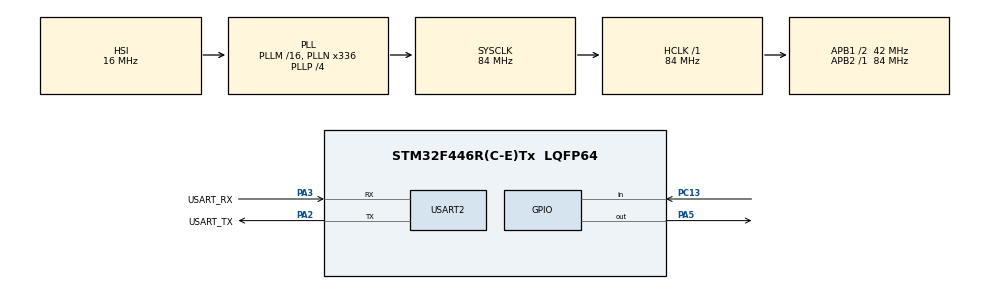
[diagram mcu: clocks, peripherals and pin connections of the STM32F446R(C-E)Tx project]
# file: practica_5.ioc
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Mcu.Family=STM32F4
Mcu.Name=STM32F446R(C-E)Tx
Mcu.Package=LQFP64
NVIC.PriorityGroup=NVIC_PRIORITYGROUP_0
PA13.GPIO_Label=TMS
PA13.Signal=SYS_JTMS-SWDIO
PA14.GPIO_Label=TCK
PA14.Signal=SYS_JTCK-SWCLK
PA2.GPIO_Label=USART_TX
PA2.Mode=Asynchronous
PA2.Signal=USART2_TX
PA3.GPIO_Label=USART_RX
PA3.Mode=Asynchronous
PA3.Signal=USART2_RX
PA5.Signal=GPIO_Output
PB3.GPIO_Label=SWO
PB3.Signal=SYS_JTDO-SWO
PC13.Signal=GPIO_Input
PC14-OSC32_IN.Signal=RCC_OSC32_IN
PC15-OSC32_OUT.Signal=RCC_OSC32_OUT
PH0-OSC_IN.Signal=RCC_OSC_IN
PH1-OSC_OUT.Signal=RCC_OSC_OUT
ProjectManager.HeapSize=0x200
ProjectManager.StackSize=0x400
ProjectManager.TargetToolchain=STM32CubeIDE
RCC.AHBFreq_Value=84000000
RCC.APB1CLKDivider=RCC_HCLK_DIV2
RCC.APB1Freq_Value=42000000
RCC.APB1TimFreq_Value=84000000
RCC.APB2Freq_Value=84000000
RCC.APB2TimFreq_Value=84000000
RCC.CortexFreq_Value=84000000
RCC.FLatency-AdvancedSettings=FLASH_LATENCY_2
RCC.HCLKFreq_Value=84000000
RCC.HSE_VALUE=8000000
RCC.HSI_VALUE=16000000
RCC.LSE_VALUE=32768
RCC.PLLN=336
RCC.PLLP=RCC_PLLP_DIV4
RCC.SYSCLKFreq_VALUE=84000000
RCC.SYSCLKSource=RCC_SYSCLKSOURCE_PLLCLK
RCC.USBFreq_Value=168000000
RCC.VCOOutputFreq_Value=336000000
USART2.VirtualMode=VM_ASYNC
board=NUCLEO-F446RE

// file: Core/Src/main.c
/* USER CODE BEGIN Header */
/**
 *****************************************************************************
 * @file           : main.c
 * @brief          : Main program body
 ******************************************************************************
 */
/* USER CODE END Header */
#include "main.h"

/* USER CODE BEGIN Includes */
#include "API_delay.h"
#include "API_debounce.h"
#include "API_uart.h"
#include "API_cmdparser.h"
/* USER CODE END Includes */

UART_HandleTypeDef huart2;

/* USER CODE BEGIN PV */

/* Períodos de parpadeo del LED en milisegundos */
#define DELAY_FAST_MS  ((tick_t)100)
#define DELAY_SLOW_MS  ((tick_t)500)

static delay_t delayLed;
static tick_t  blinkPeriod  = DELAY_FAST_MS;
static bool_t  manualMode   = false;   /* true = LED bajo control UART */

/* USER CODE END PV */

void SystemClock_Config(void);
static void MX_GPIO_Init(void);
static void MX_USART2_UART_Init(void);

/* ── Callbacks para el parser ──────────────────────────────────────────────── */

/**
 * @brief  Ejecuta la acción sobre el LED solicitada por el parser.
 *         Activa el modo manual para que el parpadeo se detenga.
 */
static void ledSetAction(led_action_t action)
{
    switch (action)
    {
        case LED_ACTION_ON:
            HAL_GPIO_WritePin(GPIOA, GPIO_PIN_5, GPIO_PIN_SET);
            break;
        case LED_ACTION_OFF:
            HAL_GPIO_WritePin(GPIOA, GPIO_PIN_5, GPIO_PIN_RESET);
            break;
        case LED_ACTION_TOGGLE:
            HAL_GPIO_TogglePin(GPIOA, GPIO_PIN_5);
            break;
        default:
            break;
    }
    manualMode = true;  /* detener el parpadeo automático */
}

/**
 * @brief  Devuelve el estado actual del LED (para el comando STATUS).
 */
static bool ledReadState(void)
{
    return (HAL_GPIO_ReadPin(GPIOA, GPIO_PIN_5) == GPIO_PIN_SET);
}

/* ── main ──────────────────────────────────────────────────────────────────── */

int main(void)
{
    HAL_Init();
    SystemClock_Config();
    MX_GPIO_Init();
    MX_USART2_UART_Init();

    if (!uartInit())
        Error_Handler();

    cmdParserInit(ledSetAction, ledReadState);

    /* Estado inicial: LED apagado, parpadeo automático */
    HAL_GPIO_WritePin(GPIOA, GPIO_PIN_5, GPIO_PIN_RESET);
    manualMode  = false;
    blinkPeriod = DELAY_FAST_MS;

    delayInit(&delayLed, blinkPeriod);
    debounceFSM_init();

    while (1)
    {
        debounceFSM_update();
        cmdPoll();

        /* Botón: en modo manual vuelve al parpadeo; en modo automático
         * alterna la velocidad de parpadeo. */
        if (readKey())
        {
            if (manualMode)
            {
                manualMode = false;
                delayInit(&delayLed, blinkPeriod); /* reiniciar para evitar toggle inmediato */
            }
            else
            {
                blinkPeriod = (blinkPeriod == DELAY_FAST_MS) ? DELAY_SLOW_MS : DELAY_FAST_MS;
                delayWrite(&delayLed, blinkPeriod);
            }
        }

        /* Parpadeo automático: solo fuera del modo manual */
        if (!manualMode && delayRead(&delayLed))
            HAL_GPIO_TogglePin(GPIOA, GPIO_PIN_5);
    }
}

void SystemClock_Config(void)
{
  RCC_OscInitTypeDef RCC_OscInitStruct = {0};
  RCC_ClkInitTypeDef RCC_ClkInitStruct = {0};
  __HAL_RCC_PWR_CLK_ENABLE();
  __HAL_PWR_VOLTAGESCALING_CONFIG(PWR_REGULATOR_VOLTAGE_SCALE3);
  RCC_OscInitStruct.OscillatorType = RCC_OSCILLATORTYPE_HSI;
  RCC_OscInitStruct.HSIState = RCC_HSI_ON;
  RCC_OscInitStruct.HSICalibrationValue = RCC_HSICALIBRATION_DEFAULT;
  RCC_OscInitStruct.PLL.PLLState = RCC_PLL_ON;
  RCC_OscInitStruct.PLL.PLLSource = RCC_PLLSOURCE_HSI;
  RCC_OscInitStruct.PLL.PLLM = 16;
  RCC_OscInitStruct.PLL.PLLN = 336;
  RCC_OscInitStruct.PLL.PLLP = RCC_PLLP_DIV4;
  RCC_OscInitStruct.PLL.PLLQ = 2;
  RCC_OscInitStruct.PLL.PLLR = 2;
  if (HAL_RCC_OscConfig(&RCC_OscInitStruct) != HAL_OK) { Error_Handler(); }
  RCC_ClkInitStruct.ClockType = RCC_CLOCKTYPE_HCLK|RCC_CLOCKTYPE_SYSCLK
                              |RCC_CLOCKTYPE_PCLK1|RCC_CLOCKTYPE_PCLK2;
  RCC_ClkInitStruct.SYSCLKSource = RCC_SYSCLKSOURCE_PLLCLK;
  RCC_ClkInitStruct.AHBCLKDivider = RCC_SYSCLK_DIV1;
  RCC_ClkInitStruct.APB1CLKDivider = RCC_HCLK_DIV2;
  RCC_ClkInitStruct.APB2CLKDivider = RCC_HCLK_DIV1;
  if (HAL_RCC_ClockConfig(&RCC_ClkInitStruct, FLASH_LATENCY_2) != HAL_OK) { Error_Handler(); }
}

static void MX_USART2_UART_Init(void)
{
  huart2.Instance = USART2;
  huart2.Init.BaudRate = 115200;
  huart2.Init.WordLength = UART_WORDLENGTH_8B;
  huart2.Init.StopBits = UART_STOPBITS_1;
  huart2.Init.Parity = UART_PARITY_NONE;
  huart2.Init.Mode = UART_MODE_TX_RX;
  huart2.Init.HwFlowCtl = UART_HWCONTROL_NONE;
  huart2.Init.OverSampling = UART_OVERSAMPLING_16;
  if (HAL_UART_Init(&huart2) != HAL_OK) { Error_Handler(); }
}

static void MX_GPIO_Init(void)
{
  GPIO_InitTypeDef GPIO_InitStruct = {0};
  __HAL_RCC_GPIOC_CLK_ENABLE();
  __HAL_RCC_GPIOH_CLK_ENABLE();
  __HAL_RCC_GPIOA_CLK_ENABLE();
  __HAL_RCC_GPIOB_CLK_ENABLE();

  HAL_GPIO_WritePin(GPIOA, GPIO_PIN_5, GPIO_PIN_RESET);

  /* Pulsador PC13: entrada con pull-up (activo en bajo) */
  GPIO_InitStruct.Pin = GPIO_PIN_13;
  GPIO_InitStruct.Mode = GPIO_MODE_INPUT;
  GPIO_InitStruct.Pull = GPIO_PULLUP;
  HAL_GPIO_Init(GPIOC, &GPIO_InitStruct);

  /* LED PA5 */
  GPIO_InitStruct.Pin = GPIO_PIN_5;
  GPIO_InitStruct.Mode = GPIO_MODE_OUTPUT_PP;
  GPIO_InitStruct.Pull = GPIO_NOPULL;
  GPIO_InitStruct.Speed = GPIO_SPEED_FREQ_LOW;
  HAL_GPIO_Init(GPIOA, &GPIO_InitStruct);
}

void Error_Handler(void)
{
  __disable_irq();
  while (1) { }
}
